# W7500x register map
Vendor: WIZnet; File version: 1.0.0
CPU: CM0 r0p0, little endian, no MPU, no FPU, 2 interrupt priority bits
Registers are 32-bit, read-write, reset 0x0 unless marked. A register's access mark holds for its fields unless they carry their own. Offsets are from the block's base; [hi:lo] are bit positions.

## SSP0
Base 0x4000A000
Same registers: SSP1 0x4000B000
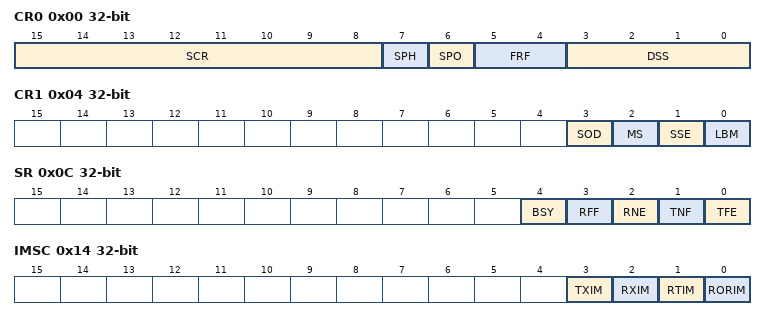
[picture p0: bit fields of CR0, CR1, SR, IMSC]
0x00 CR0 — Control register 0
  [15:8] SCR — Serial clock rate
  [7] SPH — SSPCLKOUT phase
  [6] SPO — SSPCLKOUT polarity
  [5:4] FRF — Frame Format
  [3:0] DSS — Data size select
0x04 CR1 — Control register 1
  [3] SOD — Slave-mode output disable
  [2] MS — Master or Slave mode select
  [1] SSE — Synchronous serial port enable
  [0] LBM — Loop back mode
0x08 DR — Data register
  [15:0] DATA — Transmit/Receive FIFO
0x0C SR — Status register
  [4] BSY — SSP busy flag
  [3] RFF — Receive FIFO full
  [2] RNE — Receive FIFO not empty
  [1] TNF — Transmit FIFO not full
  [0] TFE — Transmit FIFO empty
0x10 CPSR — Clock prescale register
  [7:0] CPSDVSR — Clock prescale divisor
0x14 IMSC — Interrupt mask set or clear register
  [3] TXIM — Transmit FIFO interrupt mask
  [2] RXIM — Receive FIFO interrupt mask
  [1] RTIM — Receive timeout interrupt mask
  [0] RORIM — Receive overrun interrupt mask
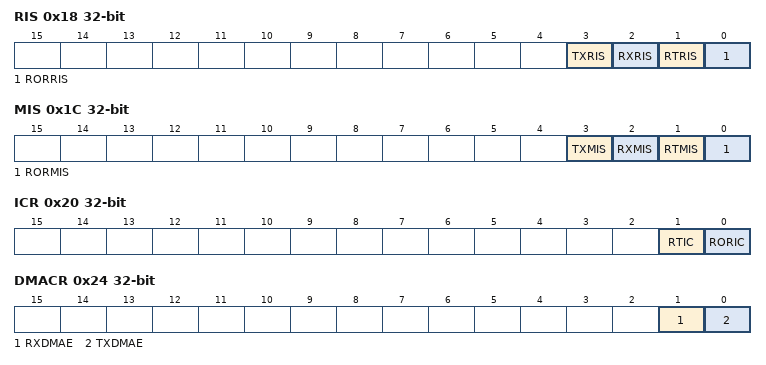
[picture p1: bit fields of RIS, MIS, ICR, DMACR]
0x18 RIS — Raw interrupt status register
  [3] TXRIS — Transmit FIFO interrupt status
  [2] RXRIS — Receive FIFO interrupt status
  [1] RTRIS — Receive timeout interrupt status
  [0] RORRIS — Receive overrun interrupt status
0x1C MIS — Masked interrupt status register
  [3] TXMIS — Transmit FIFO masked interrupt status
  [2] RXMIS — Receive FIFO masked interrupt status
  [1] RTMIS — Receive timeout masked interrupt status
  [0] RORMIS — Receive overrun masked interrupt status
0x20 ICR — Interrupt clear register
  [1] RTIC — Receive timeout interrupt clear
  [0] RORIC — Receive overrun interrupt clear
0x24 DMACR — DMA control register
  [1] RXDMAE — Transmit DMA Enable
  [0] TXDMAE — Receive DMA Enable

## RTC
Base 0x4000E000
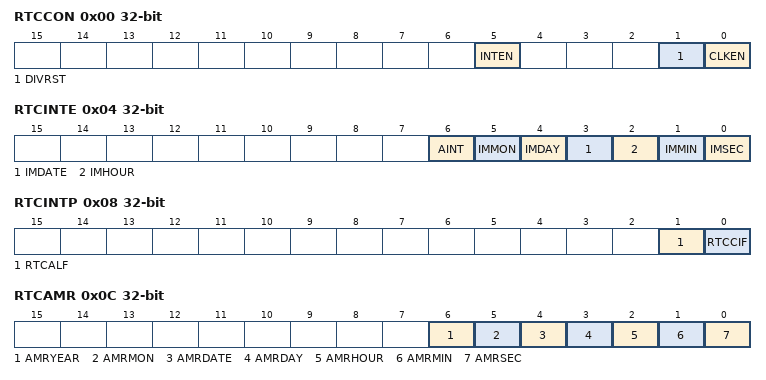
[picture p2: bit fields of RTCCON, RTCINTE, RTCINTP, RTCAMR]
0x00 RTCCON — control register
  [5] INTEN — RTC Interrupt Enable
    0=Disable; 1=Enable
  [1] DIVRST — RTC Divider Reset
    1=Reset
  [0] CLKEN — Clock Enable
    0=Disable; 1=Enable
0x04 RTCINTE — Interrupt Mask register
  [all] fields
    0=Disable; 1=Enable
  [6] AINT — RTC Alarm Interrupt Enable
  [5] IMMON — RTC Month Interrupt Enable
  [4] IMDAY — RTC Day Interrupt Enable
  [3] IMDATE — RTC Date Interrupt Enable
  [2] IMHOUR — RTC Hour Interrupt Enable
  [1] IMMIN — RTC Minute Interrupt Enable
  [0] IMSEC — RTC Second Interrupt Enable
0x08 RTCINTP — Interrupt Pending register
  [1] RTCALF — RTC Alarm interrupt pending flag
    1=Clear
  [0] RTCCIF — RTC Counter Interrupt pending flag
    1=Clear
0x0C RTCAMR — Alarm Mask register
  [all] fields
    1=Enable
  [6] AMRYEAR — RTC Alarm Mask for Year
  [5] AMRMON — RTC Alarm Mask for Month
  [4] AMRDATE — RTC Alarm Mask for Date
  [3] AMRDAY — RTC Alarm Mask for Day
  [2] AMRHOUR — RTC Alarm Mask for Hour
  [1] AMRMIN — RTC Alarm Mask for Minute
  [0] AMRSEC — RTC Alarm Mask for Second
0x10 BCDSEC — BCD Second register
  [6:0] BCDSEC — BCDSEC[6:0] bits (RTC Seconds value (0 to 59))
0x14 BCDMIN — BCD Minute register
  [6:0] BCDMIN — BCDMIN[6:0] bits (RTC Minute value (0 to 59))
0x18 BCDHOUR
  [5:0] BCDHOUR — BCDHOUR[5:0] bits (RTC Hour value (0 to 23))
0x1C BCDDAY
  [3:0] BCDDAY — BCDDAY[3:0] bits (RTC Day of Week value (1 to 7))
0x20 BCDDATE
  [5:0] BCDDATE — BCDDATE[5:0] bits (RTC Day of Month value (1 to 28, 29, 30, or 31))
0x24 BCDMON — BCD Month register
  [4:0] BCDMON — BCDMON[4:0] bits (RTC Month value (1 to 12))
0x28 BCDYEAR
  [15:0] BCDYEAR — BCDYEAR[15:0] bits (RTC Year value (0 to 4095))
0x2C PRESEC — Predetermining Second register
  [6:0] PRESEC — PRESEC[6:0] bits (RTC PREDETERMINING Seconds value (0 to 59))
0x30 PREMIN — Predetermining Minute register
  [6:0] PREMIN — PREMIN[6:0] bits (RTC Predetermining Minute value (0 to 59))
0x34 PREHOUR — Predetermining Hour register
  [5:0] PREHOUR — PREHOUR[5:0] bits (RTC Predetermining Hour value (0 to 23))
0x38 PREDAY — Predetermining Day register
  [3:0] PREDAY — PREDAY[3:0] bits (RTC Predetermining Day of Week value (1 to 7))
0x3C PREDATE — Predetermining Date register
  [5:0] PREDATE — PREDATE[3:0] bits (RTC Predetermining Day of Month value (1 to 28, 29, 30, or 31))
0x40 PREMON — Predetermining Month register
  [4:0] PREMON — PREMON[3:0] bits (RTC Predetermining Month value (1 to 12))
0x44 PREYEAR — Predetermining Year register
  [15:0] PREYEAR — PREYEAR[15:0] bits (RTC Predetermining Year value (0 to 4095))
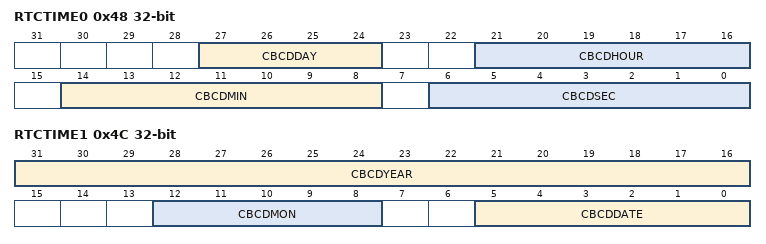
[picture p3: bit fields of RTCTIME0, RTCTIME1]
0x48 RTCTIME0 ro — Consolidated Time0 register
  [27:24] CBCDDAY — CBCDDAY[27:24] bits ( RTC Consolidated Day of Week value (1 to 7))
  [21:16] CBCDHOUR — CBCDHOUR[21:16] bits (RTC Consolidated Hour value (0 to 23))
  [14:8] CBCDMIN — CBCDMIN[14:8] bits (RTC Consolidated Minute value (0 to 59))
  [6:0] CBCDSEC — CBCDSEC[6:0] bits (RTC Consolidated Second value (0 to 59))
0x4C RTCTIME1 ro — Consolidated Time1 register
  [31:16] CBCDYEAR — CBCDYEAR[31:16] bits (RTC Consolidated Year value (0 to 4095))
  [12:8] CBCDMON — CBCDMON[12:8] bits (RTC Consolidated Month value (1 to 12))
  [5:0] CBCDDATE — CBCDDATE[5:0] bits (RTC Consolidated Day of Month value (1 to 28, 29, 30, or 31))
